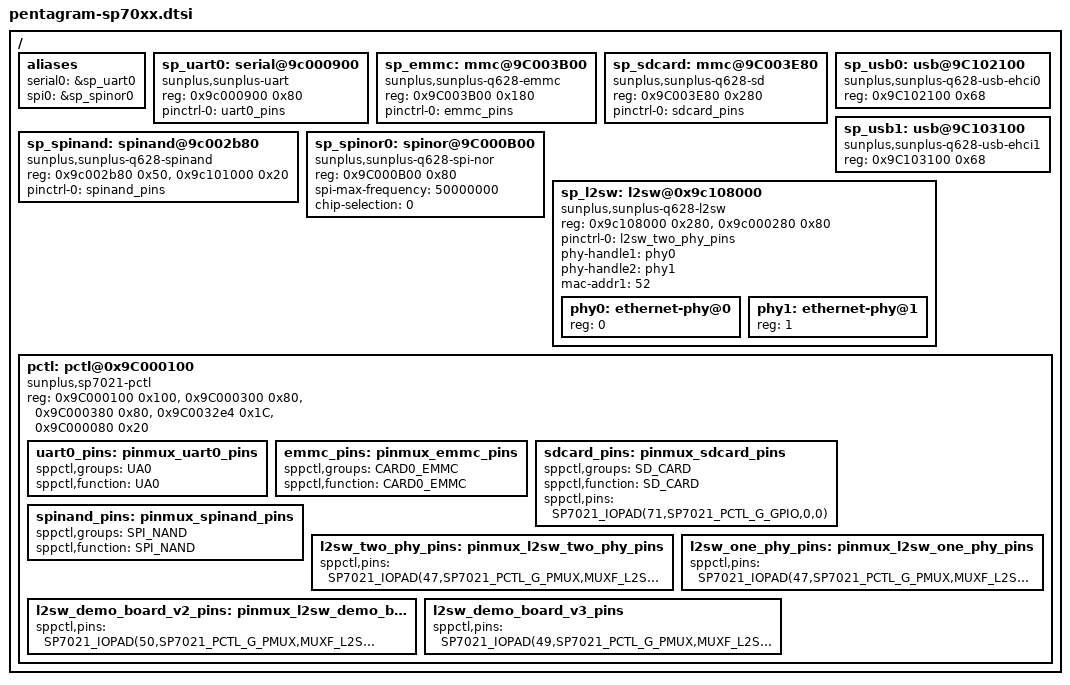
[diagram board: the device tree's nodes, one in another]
/*
 * Sunplus Pentagram sc70xx DTS
 *
 * SPDX-License-Identifier:     GPL-2.0+
 */

#include <dt-bindings/pinctrl/sp7021.h>

/ {
	aliases {
		serial0 = &sp_uart0;
		spi0 = &sp_spinor0;
	};

	sp_uart0: serial@9c000900 {
		compatible = "sunplus,sunplus-uart";
		reg = <0x9c000900 0x80>;
		pinctrl-names = "default";
		pinctrl-0 = <&uart0_pins>;
	};

	sp_emmc: mmc@9C003B00 {
		compatible = "sunplus,sunplus-q628-emmc";
		reg = <0x9C003B00 0x180>;
		pinctrl-names = "default";
		pinctrl-0 = <&emmc_pins>;
	};

	sp_sdcard: mmc@9C003E80 {
		compatible = "sunplus,sunplus-q628-sd";
		reg = <0x9C003E80 0x280>;
		pinctrl-names = "default";
		pinctrl-0 = <&sdcard_pins>;
	};

	sp_spinand: spinand@9c002b80 {
		compatible = "sunplus,sunplus-q628-spinand";
		reg-names = "spinand_reg", "bch_reg";
		reg = <0x9c002b80 0x50>, <0x9c101000 0x20>;
		pinctrl-names = "default";
		pinctrl-0 = <&spinand_pins>;
	};

	sp_usb0: usb@9C102100 {
		compatible = "sunplus,sunplus-q628-usb-ehci0";
		reg = <0x9C102100 0x68>;
	};

	sp_usb1: usb@9C103100 {
		compatible = "sunplus,sunplus-q628-usb-ehci1";
		reg = <0x9C103100 0x68>;
	};

	sp_spinor0: spinor@9C000B00 {
		compatible = "sunplus,sunplus-q628-spi-nor";
		reg = <0x9C000B00 0x80>;
		spi-max-frequency = <50000000>;
		chip-selection = <0>;
	};

	sp_l2sw: l2sw@0x9c108000 {
		compatible = "sunplus,sunplus-q628-l2sw";
		reg = <0x9c108000 0x280>, <0x9c000280 0x80>;
		reg-names = "l2sw", "moon5";
		pinctrl-names = "default";
#if 1 // Ev board
		pinctrl-0 = <&l2sw_two_phy_pins>;
#elif 0 // Demo board V2
		pinctrl-0 = <&l2sw_demo_board_v2_pins>;
#else // Demo board V3
		pinctrl-0 = <&l2sw_demo_board_v3_pins>;
#endif

		phy-handle1 = <&phy0>;
		phy-handle2 = <&phy1>;
		mac-addr1 = <52>;
		#address-cells = <1>;
		#size-cells = <0>;
		phy0: ethernet-phy@0 {
			reg = <0>;
		};
		phy1: ethernet-phy@1 {
			reg = <1>;
		};
	};

	pctl: pctl@0x9C000100 {
		compatible = "sunplus,sp7021-pctl";
		reg = <0x9C000100 0x100>, <0x9C000300 0x80>, <0x9C000380 0x80>, <0x9C0032e4 0x1C>, <0x9C000080 0x20>;

		uart0_pins: pinmux_uart0_pins {
			sppctl,groups = "UA0";
			sppctl,function = "UA0";
		};

		emmc_pins: pinmux_emmc_pins {
			sppctl,groups = "CARD0_EMMC";
			sppctl,function = "CARD0_EMMC";
		};

		sdcard_pins: pinmux_sdcard_pins {
			sppctl,groups = "SD_CARD";
			sppctl,function = "SD_CARD";
#if 0 // Demo board V3
			sppctl,pins = <	SP7021_IOPAD(91,SP7021_PCTL_G_GPIO,0,0)	>;
#else // Ev or Demo board V2
			sppctl,pins = <	SP7021_IOPAD(71,SP7021_PCTL_G_GPIO,0,0)	>;
#endif
		};

		spinand_pins: pinmux_spinand_pins {
			sppctl,groups = "SPI_NAND";
			sppctl,function = "SPI_NAND";
		};

		l2sw_two_phy_pins: pinmux_l2sw_two_phy_pins {
			sppctl,pins = <
				SP7021_IOPAD(47,SP7021_PCTL_G_PMUX,MUXF_L2SW_CLK_OUT,0)
				SP7021_IOPAD(41,SP7021_PCTL_G_PMUX,MUXF_L2SW_MAC_SMI_MDC,0)
				SP7021_IOPAD(42,SP7021_PCTL_G_PMUX,MUXF_L2SW_LED_FLASH0,0)
				SP7021_IOPAD(30,SP7021_PCTL_G_PMUX,MUXF_L2SW_LED_FLASH1,0)
				SP7021_IOPAD(51,SP7021_PCTL_G_PMUX,MUXF_L2SW_LED_ON0,0)
				SP7021_IOPAD(39,SP7021_PCTL_G_PMUX,MUXF_L2SW_LED_ON1,0)
				SP7021_IOPAD(40,SP7021_PCTL_G_PMUX,MUXF_L2SW_MAC_SMI_MDIO,0)
				SP7021_IOPAD(50,SP7021_PCTL_G_PMUX,MUXF_L2SW_P0_MAC_RMII_TXEN,0)
				SP7021_IOPAD(48,SP7021_PCTL_G_PMUX,MUXF_L2SW_P0_MAC_RMII_TXD0,0)
				SP7021_IOPAD(49,SP7021_PCTL_G_PMUX,MUXF_L2SW_P0_MAC_RMII_TXD1,0)
				SP7021_IOPAD(44,SP7021_PCTL_G_PMUX,MUXF_L2SW_P0_MAC_RMII_CRSDV,0)
				SP7021_IOPAD(45,SP7021_PCTL_G_PMUX,MUXF_L2SW_P0_MAC_RMII_RXD0,0)
				SP7021_IOPAD(46,SP7021_PCTL_G_PMUX,MUXF_L2SW_P0_MAC_RMII_RXD1,0)
				SP7021_IOPAD(43,SP7021_PCTL_G_PMUX,MUXF_L2SW_P0_MAC_RMII_RXER,0)
				SP7021_IOPAD(38,SP7021_PCTL_G_PMUX,MUXF_L2SW_P1_MAC_RMII_TXEN,0)
				SP7021_IOPAD(36,SP7021_PCTL_G_PMUX,MUXF_L2SW_P1_MAC_RMII_TXD0,0)
				SP7021_IOPAD(37,SP7021_PCTL_G_PMUX,MUXF_L2SW_P1_MAC_RMII_TXD1,0)
				SP7021_IOPAD(32,SP7021_PCTL_G_PMUX,MUXF_L2SW_P1_MAC_RMII_CRSDV,0)
				SP7021_IOPAD(33,SP7021_PCTL_G_PMUX,MUXF_L2SW_P1_MAC_RMII_RXD0,0)
				SP7021_IOPAD(34,SP7021_PCTL_G_PMUX,MUXF_L2SW_P1_MAC_RMII_RXD1,0)
				SP7021_IOPAD(31,SP7021_PCTL_G_PMUX,MUXF_L2SW_P1_MAC_RMII_RXER,0)
			>;
		};

		l2sw_one_phy_pins: pinmux_l2sw_one_phy_pins {
			sppctl,pins = <
				SP7021_IOPAD(47,SP7021_PCTL_G_PMUX,MUXF_L2SW_CLK_OUT,0)
				SP7021_IOPAD(41,SP7021_PCTL_G_PMUX,MUXF_L2SW_MAC_SMI_MDC,0)
				SP7021_IOPAD(42,SP7021_PCTL_G_PMUX,MUXF_L2SW_LED_FLASH0,0)
				SP7021_IOPAD(51,SP7021_PCTL_G_PMUX,MUXF_L2SW_LED_ON0,0)
				SP7021_IOPAD(40,SP7021_PCTL_G_PMUX,MUXF_L2SW_MAC_SMI_MDIO,0)
				SP7021_IOPAD(50,SP7021_PCTL_G_PMUX,MUXF_L2SW_P0_MAC_RMII_TXEN,0)
				SP7021_IOPAD(48,SP7021_PCTL_G_PMUX,MUXF_L2SW_P0_MAC_RMII_TXD0,0)
				SP7021_IOPAD(49,SP7021_PCTL_G_PMUX,MUXF_L2SW_P0_MAC_RMII_TXD1,0)
				SP7021_IOPAD(44,SP7021_PCTL_G_PMUX,MUXF_L2SW_P0_MAC_RMII_CRSDV,0)
				SP7021_IOPAD(45,SP7021_PCTL_G_PMUX,MUXF_L2SW_P0_MAC_RMII_RXD0,0)
				SP7021_IOPAD(46,SP7021_PCTL_G_PMUX,MUXF_L2SW_P0_MAC_RMII_RXD1,0)
				SP7021_IOPAD(43,SP7021_PCTL_G_PMUX,MUXF_L2SW_P0_MAC_RMII_RXER,0)
			>;
		};

		l2sw_demo_board_v2_pins: pinmux_l2sw_demo_board_v2_pins {
			sppctl,pins = <
				SP7021_IOPAD(50,SP7021_PCTL_G_PMUX,MUXF_L2SW_CLK_OUT,0)
				SP7021_IOPAD(44,SP7021_PCTL_G_PMUX,MUXF_L2SW_MAC_SMI_MDC,0)
				SP7021_IOPAD(54,SP7021_PCTL_G_PMUX,MUXF_L2SW_LED_FLASH0,0)
				SP7021_IOPAD(45,SP7021_PCTL_G_PMUX,MUXF_L2SW_LED_ON0,0)
				SP7021_IOPAD(43,SP7021_PCTL_G_PMUX,MUXF_L2SW_MAC_SMI_MDIO,0)
				SP7021_IOPAD(53,SP7021_PCTL_G_PMUX,MUXF_L2SW_P0_MAC_RMII_TXEN,0)
				SP7021_IOPAD(51,SP7021_PCTL_G_PMUX,MUXF_L2SW_P0_MAC_RMII_TXD0,0)
				SP7021_IOPAD(52,SP7021_PCTL_G_PMUX,MUXF_L2SW_P0_MAC_RMII_TXD1,0)
				SP7021_IOPAD(47,SP7021_PCTL_G_PMUX,MUXF_L2SW_P0_MAC_RMII_CRSDV,0)
				SP7021_IOPAD(48,SP7021_PCTL_G_PMUX,MUXF_L2SW_P0_MAC_RMII_RXD0,0)
				SP7021_IOPAD(49,SP7021_PCTL_G_PMUX,MUXF_L2SW_P0_MAC_RMII_RXD1,0)
				SP7021_IOPAD(46,SP7021_PCTL_G_PMUX,MUXF_L2SW_P0_MAC_RMII_RXER,0)
			>;
		};

		l2sw_demo_board_v3_pins: l2sw_demo_board_v3_pins {
			sppctl,pins = <
				SP7021_IOPAD(49,SP7021_PCTL_G_PMUX,MUXF_L2SW_CLK_OUT,0)
				SP7021_IOPAD(44,SP7021_PCTL_G_PMUX,MUXF_L2SW_MAC_SMI_MDC,0)
				SP7021_IOPAD(43,SP7021_PCTL_G_PMUX,MUXF_L2SW_MAC_SMI_MDIO,0)
				SP7021_IOPAD(52,SP7021_PCTL_G_PMUX,MUXF_L2SW_P0_MAC_RMII_TXEN,0)
				SP7021_IOPAD(50,SP7021_PCTL_G_PMUX,MUXF_L2SW_P0_MAC_RMII_TXD0,0)
				SP7021_IOPAD(51,SP7021_PCTL_G_PMUX,MUXF_L2SW_P0_MAC_RMII_TXD1,0)
				SP7021_IOPAD(46,SP7021_PCTL_G_PMUX,MUXF_L2SW_P0_MAC_RMII_CRSDV,0)
				SP7021_IOPAD(47,SP7021_PCTL_G_PMUX,MUXF_L2SW_P0_MAC_RMII_RXD0,0)
				SP7021_IOPAD(48,SP7021_PCTL_G_PMUX,MUXF_L2SW_P0_MAC_RMII_RXD1,0)
				SP7021_IOPAD(45,SP7021_PCTL_G_PMUX,MUXF_L2SW_P0_MAC_RMII_RXER,0)
				SP7021_IOPAD(59,SP7021_PCTL_G_PMUX,MUXF_L2SW_P1_MAC_RMII_TXEN,0)
				SP7021_IOPAD(57,SP7021_PCTL_G_PMUX,MUXF_L2SW_P1_MAC_RMII_TXD0,0)
				SP7021_IOPAD(58,SP7021_PCTL_G_PMUX,MUXF_L2SW_P1_MAC_RMII_TXD1,0)
				SP7021_IOPAD(54,SP7021_PCTL_G_PMUX,MUXF_L2SW_P1_MAC_RMII_CRSDV,0)
				SP7021_IOPAD(55,SP7021_PCTL_G_PMUX,MUXF_L2SW_P1_MAC_RMII_RXD0,0)
				SP7021_IOPAD(56,SP7021_PCTL_G_PMUX,MUXF_L2SW_P1_MAC_RMII_RXD1,0)
				SP7021_IOPAD(53,SP7021_PCTL_G_PMUX,MUXF_L2SW_P1_MAC_RMII_RXER,0)
			>;
		};
	};
};
